VERSION ""

NS_ :

BS_:

BU_:

BO_ 158 ID_9E: 8 XXX
 SG_ CLUTCH_ALT : 5|1@0+ (1,0) [0|1] "" XXX
 SG_ NEUTRAL_SW : 0|1@0+ (1,0) [0|1] "" XXX

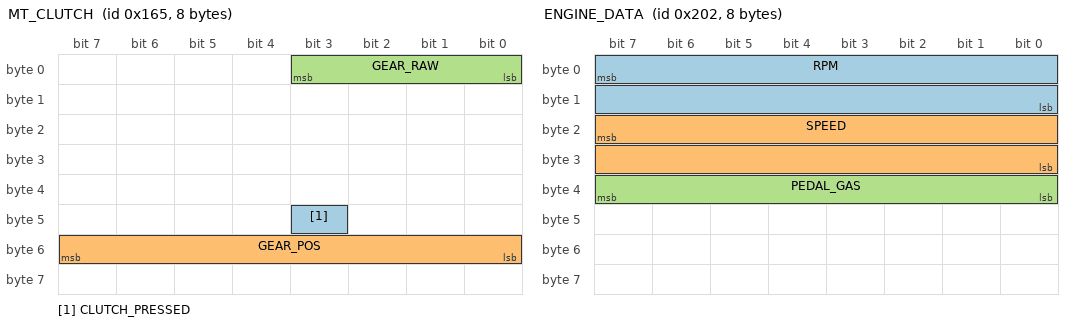
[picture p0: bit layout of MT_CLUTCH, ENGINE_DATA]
BO_ 357 MT_CLUTCH: 8 XXX
 SG_ CLUTCH_PRESSED : 43|1@0+ (1,0) [0|1] "" XXX
 SG_ GEAR_POS : 55|8@0+ (1,0) [0|255] "" XXX
 SG_ GEAR_RAW : 3|4@0+ (1,0) [0|15] "" XXX

BO_ 514 ENGINE_DATA: 8 XXX
 SG_ RPM : 7|16@0+ (0.25,0) [0|8500] "rpm" XXX
 SG_ SPEED : 23|16@0+ (0.01,0) [0|32767] "kph" XXX
 SG_ PEDAL_GAS : 39|8@0+ (0.3921568627,0) [0|100] "%" XXX

BO_ 513 GEAR: 8 XXX
 SG_ GEAR : 51|4@0+ (1,0) [0|15] "" XXX

BO_ 608 STEER: 8 XXX
 SG_ STEER_ANGLE : 7|16@0+ (-0.1,0) [-3276.7|3276.7] "deg" XXX

BO_ 576 STEER_TORQUE: 8 XXX
 SG_ STEER_TORQUE_SENSOR : 7|16@0+ (1,0) [-32768|32767] "" XXX
 SG_ STEER_TORQUE_MOTOR : 23|16@0+ (1,0) [-32768|32767] "" XXX

BO_ 582 STEER_RATE: 8 XXX
 SG_ STEER_ANGLE_RATE : 7|16@0+ (1,0) [-32768|32767] "" XXX
 SG_ LKAS_BLOCK : 23|1@0+ (1,0) [0|1] "" XXX

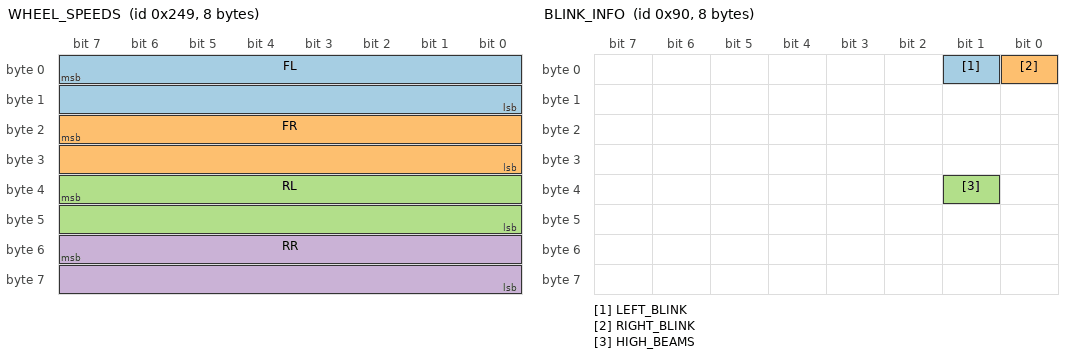
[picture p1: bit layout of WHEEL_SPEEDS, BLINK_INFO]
BO_ 585 WHEEL_SPEEDS: 8 XXX
 SG_ FL : 7|16@0+ (0.01,0) [0|250] "kph" XXX
 SG_ FR : 23|16@0+ (0.01,0) [0|250] "kph" XXX
 SG_ RL : 39|16@0+ (0.01,0) [0|250] "kph" XXX
 SG_ RR : 55|16@0+ (0.01,0) [0|250] "kph" XXX

BO_ 144 BLINK_INFO: 8 XXX
 SG_ LEFT_BLINK : 1|1@0+ (1,0) [0|1] "" XXX
 SG_ RIGHT_BLINK : 0|1@0+ (1,0) [0|1] "" XXX
 SG_ HIGH_BEAMS : 33|1@0+ (1,0) [0|1] "" XXX

BO_ 1024 BSM: 8 XXX
 SG_ LEFT_BS_STATUS : 7|1@0+ (1,0) [0|1] "" XXX
 SG_ RIGHT_BS_STATUS : 15|1@0+ (1,0) [0|1] "" XXX

BO_ 789 PEDALS: 8 XXX
 SG_ BRAKE_ON : 16|1@0+ (1,0) [0|1] "" XXX
 SG_ STANDSTILL : 23|1@0+ (1,0) [0|1] "" XXX

BO_ 528 BRAKE: 8 XXX
 SG_ BRAKE_PRESSURE : 7|16@0+ (1,0) [0|65535] "" XXX

BO_ 1238 SEATBELT: 8 XXX
 SG_ DRIVER_SEATBELT : 57|1@0+ (1,0) [0|1] "" XXX

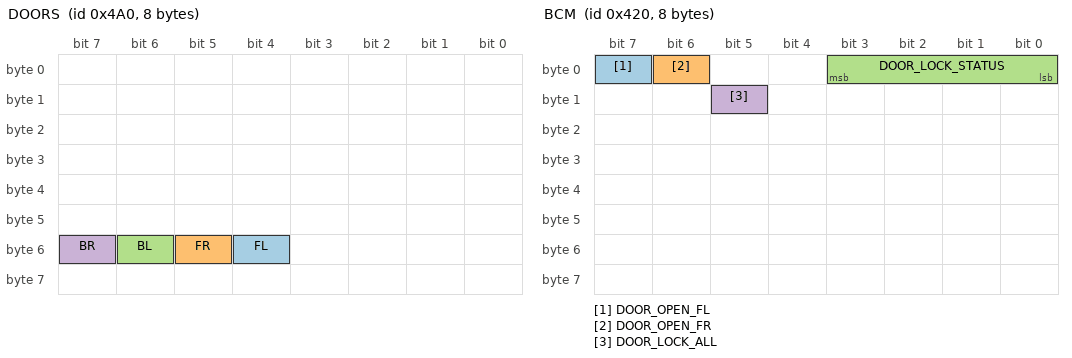
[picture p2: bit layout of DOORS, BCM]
BO_ 1184 DOORS: 8 XXX
 SG_ FL : 52|1@0+ (1,0) [0|1] "" XXX
 SG_ FR : 53|1@0+ (1,0) [0|1] "" XXX
 SG_ BL : 54|1@0+ (1,0) [0|1] "" XXX
 SG_ BR : 55|1@0+ (1,0) [0|1] "" XXX

BO_ 1056 BCM: 8 XXX
 SG_ DOOR_OPEN_FL : 7|1@0+ (1,0) [0|1] "" XXX
 SG_ DOOR_OPEN_FR : 6|1@0+ (1,0) [0|1] "" XXX
 SG_ DOOR_LOCK_STATUS : 3|4@0+ (1,0) [0|15] "" XXX
 SG_ DOOR_LOCK_ALL : 13|1@0+ (1,0) [0|1] "" XXX

BO_ 354 CRZ_CTRL: 8 XXX
 SG_ CRZ_AVAILABLE : 29|1@0+ (1,0) [0|1] "" XXX
 SG_ CRZ_ACTIVE : 28|1@0+ (1,0) [0|1] "" XXX

BO_ 1064 CRZ_EVENTS: 8 XXX
 SG_ CRZ_SPEED : 7|8@0+ (1,0) [0|255] "kph" XXX

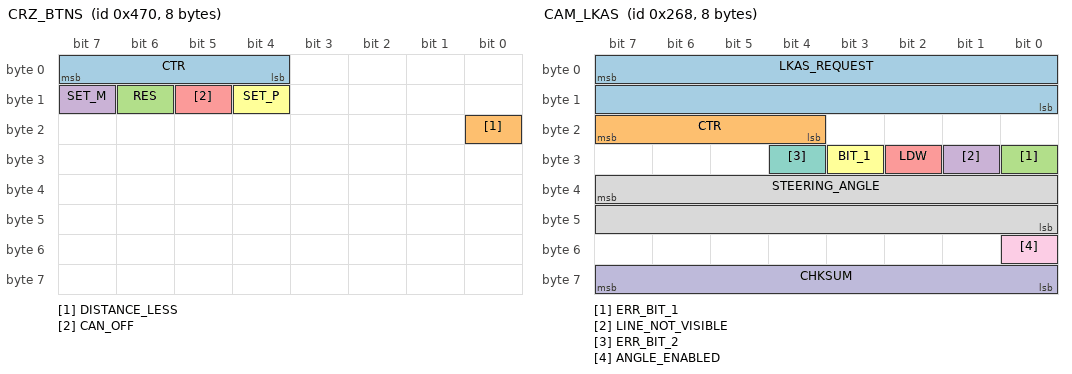
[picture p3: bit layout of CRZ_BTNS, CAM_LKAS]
BO_ 1136 CRZ_BTNS: 8 XXX
 SG_ CTR : 7|4@0+ (1,0) [0|15] "" XXX
 SG_ DISTANCE_LESS : 16|1@0+ (1,0) [0|1] "" XXX
 SG_ RES : 14|1@0+ (1,0) [0|1] "" XXX
 SG_ SET_M : 15|1@0+ (1,0) [0|1] "" XXX
 SG_ CAN_OFF : 13|1@0+ (1,0) [0|1] "" XXX
 SG_ SET_P : 12|1@0+ (1,0) [0|1] "" XXX

BO_ 616 CAM_LKAS: 8 XXX
 SG_ LKAS_REQUEST : 7|16@0+ (1,0) [-2048|2047] "" XXX
 SG_ CTR : 23|4@0+ (1,0) [0|15] "" XXX
 SG_ ERR_BIT_1 : 24|1@0+ (1,0) [0|1] "" XXX
 SG_ LINE_NOT_VISIBLE : 25|1@0+ (1,0) [0|1] "" XXX
 SG_ LDW : 26|1@0+ (1,0) [0|1] "" XXX
 SG_ BIT_1 : 27|1@0+ (1,0) [0|1] "" XXX
 SG_ ERR_BIT_2 : 28|1@0+ (1,0) [0|1] "" XXX
 SG_ STEERING_ANGLE : 39|16@0+ (1,0) [-2048|2047] "" XXX
 SG_ ANGLE_ENABLED : 48|1@0+ (1,0) [0|1] "" XXX
 SG_ CHKSUM : 63|8@0+ (1,0) [0|255] "" XXX

BO_ 1157 CAM_LANEINFO: 8 XXX
 SG_ LANE_LINES : 1|2@0+ (1,0) [0|3] "" XXX

VAL_ 513 GEAR 15 "N" 14 "P" 13 "R" 1 "D" ;
VAL_ 357 GEAR_POS 2 "6th" 3 "5th" 4 "4th" 5 "3rd" 7 "2nd" 13 "1st" 14 "1st_hi" ;
VAL_ 357 GEAR_RAW 0 "Neutral" 1 "1st" 2 "2nd" 3 "3rd" 4 "4th" 5 "5th" 6 "6th" 7 "6th_巡航" 15 "Reverse" ;
